# USB0_MMR_MMRVBP_USBSS_CMN register map
Vendor: Texas Instruments
Peripheral module from a debugger description file (folder J721S2).
Registers are 32-bit, access per field, reset 0x0 unless marked. A register's access mark holds for its fields unless they carry their own. Offsets are as the file gives them; lines under a group give offsets from that group; [hi:lo] are bit positions; {n}, {i} and the like mark numbered series; 'fields as' and 'values as' point back to an identical list; <NAME> marks a mode.

## USB0_MMR_MMRVBP_USBSS_CMN
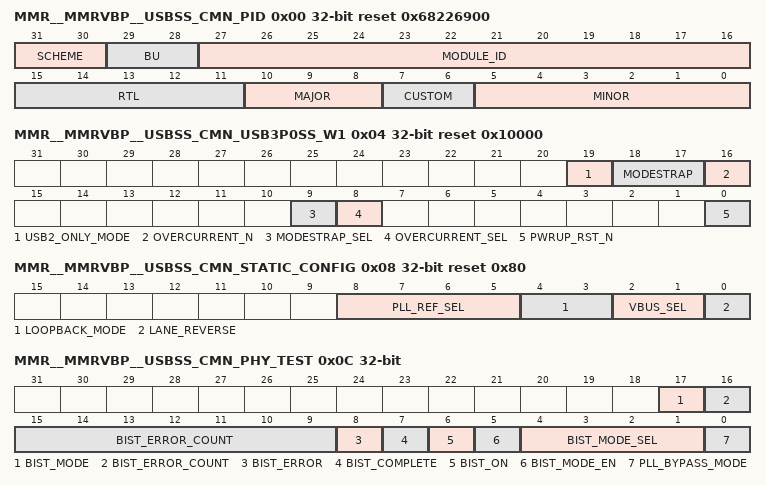
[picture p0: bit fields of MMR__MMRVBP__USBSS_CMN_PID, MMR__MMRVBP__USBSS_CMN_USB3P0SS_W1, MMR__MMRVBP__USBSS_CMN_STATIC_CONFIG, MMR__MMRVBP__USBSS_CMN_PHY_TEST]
0x00 MMR__MMRVBP__USBSS_CMN_PID ro reset 0x68226900 — The Revision Register contains the major and minor revisions for the module.
  [31:30] SCHEME — PID register scheme
  [29:28] BU — Business Unit: 10 = Processors
  [27:16] MODULE_ID
  [15:11] RTL — RTL revision. Will vary depending on release.
  [10:8] MAJOR — Major revision
  [7:6] CUSTOM
  [5:0] MINOR — Minor revision
0x04 MMR__MMRVBP__USBSS_CMN_USB3P0SS_W1 reset 0x10000 — Wrapper register containing soft reset, mode selection, and overcurrent indicator.
  [19] USB2_ONLY_MODE rw — Selects USB2 only mode. Has to be written before setting pwrup_rst_n bit. This bit has to be set when SERDES is not assigned to this USB instance. For example, when the Wiz is configured to allocate the serdes lanes for another function, like PCIe. Without setting this bit in those cases, the Controller will not function even at USB2 speeds, or may be erratic.
  [18:17] MODESTRAP rw — Modestrap input to the Controller. Has to be written before setting pwrup_rst_n bit. 00 - Controller not configured as Host or Device, 01 - Controller is initially configured as Host, 10 - Controller is initially configured as Device. Please refer to section 5.2 in DRD Controller Design Specification R1 for more information.
  [16] OVERCURRENT_N rw — Overcurrent indicator to the Controller
  [9] MODESTRAP_SEL rw — Select signal. Has to be written before setting pwrup_rst_n bit. 1 - modestrap MMR bits are used, 0 - usb_mode_strap input is used
  [8] OVERCURRENT_SEL rw — Overcurrent MMR select. Has to be written before setting pwrup_rst_n bit. 1 - overcurrent MMR bit is used, 0 - port_overcurrent_n input is used
  [0] PWRUP_RST_N rw — Power up reset for the Controller. Set this bit after initialization steps like modestrap configuration, extended capability register configuration etc.
0x08 MMR__MMRVBP__USBSS_CMN_STATIC_CONFIG reset 0x80 — Wrapper register containing static settings. All bits in this register have to be written before setting pwrup_rst_n bit in USB3P0SS_W1 register. All bits in this register directly drive the USB2 PHY inputs. Please refer to USB2 PHY user guide for more information.
  [8:5] PLL_REF_SEL rw — This register directly drives the pllrefsel[3:0] input to USB2 PHY. Indicates the frequency of the REF_CLOCK input used by the USB PLL. This value should match the frequency value of either the HFOSC0 or HFOSC1 oscillator as selected by the USB0_CLKSEL register. Field values (Others are reserved): 4'b0000 - 9.6 MHz 4'b0001 - 10 MHz 4'b0010 - 12 MHz 4'b0011 - 18.2 MHz 4'b0100 - 20 MHz 4'b0101 - 24 MHz 4'b0110 - 25 MHz 4'b0111 - 26 MHz 4'b1000 - 38.4 MHz 4'b1001 - 40 MHz 4'b1010 - 48 MHz 4'b1011 - 50 MHz 4'b1100 - 52 MHz
  [4:3] LOOPBACK_MODE rw — This register directly drives the loopback[1:0] input to USB2 PHY. Loopback mode selection - 00: Loopback OFF, 01: LS Loopback ON, 10: FS Loopback ON, 11: HS Loopback ON.
  [2:1] VBUS_SEL rw — This register directly drives the vbus_sel[1:0] input to the PHY. VBUS select - 00: VBUS = 5.25V/3.3V, 01: VBUS/3 external divider is active, so VBUS could be upto 11V.
  [0] LANE_REVERSE rw — This register directly drives the lane_reverse input to USB2 PHY. Lane reverse selection. When set, this bit indicates that D+ and D- lines have to be swapped.
0x0C MMR__MMRVBP__USBSS_CMN_PHY_TEST — Register containing PLL bypass select, BIST control and status
  [17] BIST_MODE rw — Set for bist mode. This is used for overriding PHY ports for BIST.
  [16:9] BIST_ERROR_COUNT ro — Number of bytes that have errors while running BIST. The count resets when bist_on is set.
  [8] BIST_ERROR ro — If set, this bit indicates that BIST completed with error.
  [7] BIST_COMPLETE ro — If set, this bit indicates that the BIST operation is completed.
  [6] BIST_ON rw — Setting this bit starts the BIST operation.
  [5] BIST_MODE_EN rw — BIST Mode Enable. 0 = BIST not enabled, 1 = BIST enabled
  [4:1] BIST_MODE_SEL rw — BIST Mode Selection. bist_mode_sel[3]: 0 = 8-bit interface, 1 = 16-bit interface; bist_mode_sel[2]: 0 = error injection disabled, 1 = error injection enabled; bist_mode_sel[1]: 0 = device mode, 1 = host mode; bist_mode_sel[0]: 0 = High Speed mode, 1 = Full Speed mode.
  [0] PLL_BYPASS_MODE rw — Setting this bit disables the PLL clock and bypasses it with PLL reference clock.
0x10 MMR__MMRVBP__USBSS_CMN_USB3P0SS_DEBUG_CTRL — USB Controller debug selection register
  [4:0] DEBUG_SEL rw — Debug selection
0x14 MMR__MMRVBP__USBSS_CMN_USB3P0SS_DEBUG_INFO ro — USB Controller debug information register
  [31:0] DEBUG_INFO — Debug information selected by debug_sel
0x18 MMR__MMRVBP__USBSS_CMN_USB3P0SS_DEBUG_LINK_STATE ro — USB Controller debug link state information
  [30:0] DEBUG_LINK_STATE — Debug link state information
0x1C MMR__MMRVBP__USBSS_CMN_USB3P0SS_DEVICE_CTRL — Register for device control
  [0] DEV_WAKEUP rw — Set this bit to trigger device wakeup interrupt on irq_intr[7]
